# AVR128DB28 device description
Architecture: AVR8X; Family: AVR
Registers are 8-bit, read-write, reset 0x0 unless marked. A register's access mark holds for its fields unless they carry their own. Offsets are from the block's base; [hi:lo] are bit positions; {n}, {i} and the like mark numbered series; <NAME> marks a mode.

## AC — Analog Comparator
Instances: AC0 0x0680, AC1 0x0688, AC2 0x0690
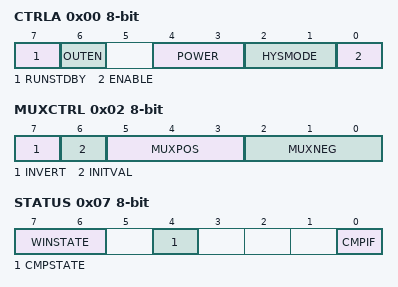
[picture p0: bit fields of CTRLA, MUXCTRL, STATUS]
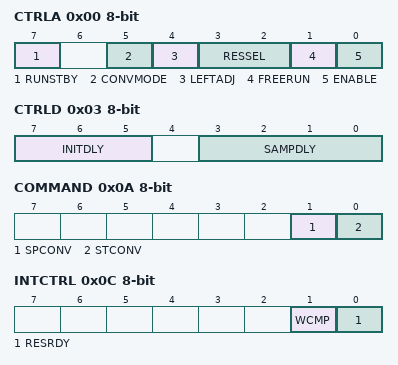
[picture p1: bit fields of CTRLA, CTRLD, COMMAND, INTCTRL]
0x00 CTRLA — Control A
  [7] RUNSTDBY — Run in Standby Mode
  [6] OUTEN — Output Pad Enable
  [4:3] POWER — Power profile
    0=PROFILE0 (Power profile 0, Shortest response time, highest consumption); 1=PROFILE1 (Power profile 1); 2=PROFILE2 (Power profile 2)
  [2:1] HYSMODE — Hysteresis Mode
    0=NONE (No hysteresis); 1=SMALL (Small hysteresis); 2=MEDIUM (Medium hysteresis); 3=LARGE (Large hysteresis)
  [0] ENABLE
0x01 CTRLB — Control B
  [1:0] WINSEL — Window selection mode
    0=DISABLED (Window function disabled); 1=UPSEL1 (Select ACn+1 as upper limit in window compare); 2=UPSEL2 (Select ACn+2 as upper limit in window compare)
0x02 MUXCTRL — Mux Control A
  [7] INVERT — Invert AC Output
  [6] INITVAL — AC Output Initial Value
    0=LOW (Output initialized to 0); 1=HIGH (Output initialized to 1)
  [5:3] MUXPOS — Positive Input MUX Selection
    {v}=AINP{v} (Positive Pin {v}) (v=0..3)
  [2:0] MUXNEG — Negative Input MUX Selection
    0=AINN0 (Negative Pin 0); 1=AINN1 (Negative Pin 1); 2=AINN2 (Negative Pin 2); 3=DACREF (DAC Reference)
0x05 DACREF reset 0xFF — DAC Voltage Reference
0x06 INTCTRL (modes: NORMAL when AC.CTRLB.WINSEL=0x00; WINDOW when AC.CTRLB.WINSEL=0x01 0x02) — Interrupt Control
  [0] CMP — Interrupt Enable
  [5:4] INTMODE <NORMAL> — Interrupt Mode
    0=BOTHEDGE (Positive and negative inputs crosses); 2=NEGEDGE (Positive input goes below negative input); 3=POSEDGE (Positive input goes above negative input)
  [5:4] INTMODE <WINDOW> — Interrupt Mode
    0=ABOVE (Window interrupt when input above both references); 1=INSIDE (Window interrupt when input betweeen references); 2=BELOW (Window interrupt when input below both references); 3=OUTSIDE (Window interrupt when input outside reference)
0x07 STATUS
  [7:6] WINSTATE ro — Analog Comparator Window State
    0=ABOVE (Above window); 1=INSIDE (Inside window); 2=BELOW (Below window)
  [4] CMPSTATE ro — Analog Comparator State
  [0] CMPIF — Analog Comparator Interrupt Flag

## ADC — Analog to Digital Converter
Instances: ADC0 0x0600
0x00 CTRLA — Control A
  [7] RUNSTBY — Run standby mode
  [5] CONVMODE — Conversion mode
    0=SINGLEENDED (Single-Ended mode); 1=DIFF (Differential mode)
  [4] LEFTADJ — Left adjust result
  [3:2] RESSEL — Resolution selection
    0=12BIT (12-bit mode); 1=10BIT (10-bit mode)
  [1] FREERUN — Free running mode
  [0] ENABLE — ADC Enable
0x01 CTRLB — Control B
  [2:0] SAMPNUM — Accumulation Samples
    0=NONE (No accumulation); 1=ACC2 (2 results accumulated); 2=ACC4 (4 results accumulated); 3=ACC8 (8 results accumulated); 4=ACC16 (16 results accumulated); 5=ACC32 (32 results accumulated); 6=ACC64 (64 results accumulated); 7=ACC128 (128 results accumulated)
0x02 CTRLC — Control C
  [3:0] PRESC — Clock Pre-scaler
    0=DIV2 (CLK_PER divided by 2); 1=DIV4 (CLK_PER divided by 4); 2=DIV8 (CLK_PER divided by 8); 3=DIV12 (CLK_PER divided by 12); 4=DIV16 (CLK_PER divided by 16); 5=DIV20 (CLK_PER divided by 20); 6=DIV24 (CLK_PER divided by 24); 7=DIV28 (CLK_PER divided by 28); 8=DIV32 (CLK_PER divided by 32); 9=DIV48 (CLK_PER divided by 48); 10=DIV64 (CLK_PER divided by 64); 11=DIV96 (CLK_PER divided by 96); 12=DIV128 (CLK_PER divided by 128); 13=DIV256 (CLK_PER divided by 256)
0x03 CTRLD — Control D
  [7:5] INITDLY — Initial Delay Selection
    0=DLY0 (Delay 0 CLK_ADC cycles); 1=DLY16 (Delay 16 CLK_ADC cycles); 2=DLY32 (Delay 32 CLK_ADC cycles); 3=DLY64 (Delay 64 CLK_ADC cycles); 4=DLY128 (Delay 128 CLK_ADC cycles); 5=DLY256 (Delay 256 CLK_ADC cycles)
  [3:0] SAMPDLY — Sampling Delay Selection
    {v}=DLY{v} (Delay {v} CLK_ADC cycles) (v=0..15)
0x04 CTRLE — Control E
  [2:0] WINCM — Window Comparator Mode
    0=NONE (No Window Comparison); 1=BELOW (Below Window); 2=ABOVE (Above Window); 3=INSIDE (Inside Window); 4=OUTSIDE (Outside Window)
0x05 SAMPCTRL — Sample Control
  [7:0] SAMPLEN — Sample lenght
0x08 MUXPOS — Positive mux input
  [6:0] MUXPOS — Analog Channel Selection Bits
    {v}=AIN{v} (ADC input pin {v}) (v=0..21); 64=GND (Ground); 66=TEMPSENSE (Temperature sensor); 68=VDDDIV10 (VDD/10); 69=VDDIO2DIV10 (VDDIO2/10); 72=DAC0; 73=DACREF0 (AC0 DAC Voltage Reference); 74=DACREF1 (AC1 DAC Voltage Reference); 75=DACREF2 (AC2 DAC Voltage Reference)
0x09 MUXNEG — Negative mux input
  [6:0] MUXNEG — Analog Channel Selection Bits
    {v}=AIN{v} (ADC input pin {v}) (v=0..15); 64=GND (Ground); 72=DAC0
0x0A COMMAND
  [1] SPCONV — Stop Conversion
  [0] STCONV — Start Conversion
0x0B EVCTRL — Event Control
  [0] STARTEI — Start Event Input Enable
0x0C INTCTRL — Interrupt Control
  [1] WCMP — Window Comparator Interrupt Enable
  [0] RESRDY — Result Ready Interrupt Enable
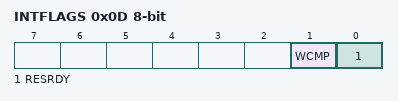
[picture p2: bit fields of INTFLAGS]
0x0D INTFLAGS — Interrupt Flags
  [1] WCMP — Window Comparator Flag
  [0] RESRDY — Result Ready Flag
0x0E DBGCTRL — Debug Control
  [0] DBGRUN — Debug run
0x0F TEMP — Temporary Data
  [7:0] TEMP — Temporary
0x10 RES 16-bit ro reset not defined — ADC Accumulator Result
0x12 WINLT 16-bit reset not defined — Window comparator low threshold
0x14 WINHT 16-bit reset not defined — Window comparator high threshold
